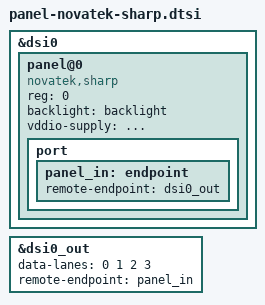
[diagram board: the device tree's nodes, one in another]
&dsi0 {
	panel@0 {
		compatible = "novatek,sharp";
		reg = <0>;

		backlight = <&backlight>;
		vddio-supply = <&...>;

		port {
			panel_in: endpoint {
				remote-endpoint = <&dsi0_out>;
			};
		};
	};
};

&dsi0_out {
	data-lanes = <0 1 2 3>;
	remote-endpoint = <&panel_in>;
};
